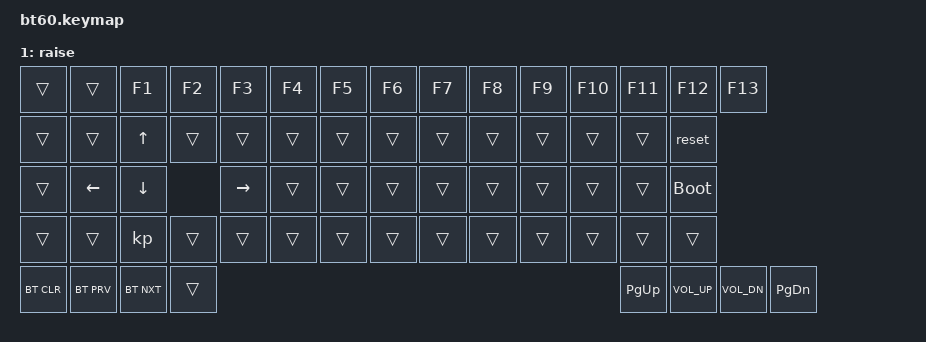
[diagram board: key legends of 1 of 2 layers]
#include <behaviors.dtsi>
#include <dt-bindings/zmk/keys.h>
#include <dt-bindings/zmk/bt.h>

/ {
	keymap {
		compatible = "zmk,keymap";

		default_layer {
				// ------------------------------------------------------------------------------------------
				// | ESC |  GRAVE |  1  |  2  |  3  |  4  |  5  |  6  |  7  |  8  |  9  |  0  |  -  |  =  |   "|"   |
				// | TAB  |  Q  |  W  |  E  |  R  |  T  |  Y  |  U  |  I  |  O  |  P  |  [  |  ]  |   BKSP   |
				// | CAPS  |  A  |  S  |  D  |  F  |  G  |  H  |  J  |  K  |  L  |  ;  |  '  |     ENTER    |
				// |  SHIFT    |  Z  |  X  |  C  |  V  |  B  |  N  |  M  |  ,  |  .  | /   |     SHIFT      |
				// |  CTL  |  ALT  |  CMD  |                     SPACE               |   LEFT   |  UP  | DOWN |  RIGHT |
				// ------------------------------------------------------------------------------------------
			bindings = <
				&kp ESC &kp GRAVE &kp N1 &kp N2 &kp N3 &kp N4 &kp N5 &kp N6 &kp N7 &kp  N8   &kp  N9 &kp  N0  &kp MINUS &kp EQUAL &kp BSLH
				&kp TAB  &kp Q  &kp W  &kp E  &kp R  &kp T  &kp Y  &kp U  &kp  I    &kp  O  &kp  P   &kp LBKT &kp RBKT  &kp BSPC
				&kp CLCK  &kp A  &kp S  &kp D  &kp F  &kp G  &kp H  &kp J  &kp  K    &kp  L  &kp SEMI &kp SQT           &kp RET
				&kp LSHFT  &kp Z  &kp X  &kp C  &kp V  &kp B  &kp N  &kp M  &kp COMMA &kp DOT &kp FSLH    &kp RSHFT    &mo 1
				&kp LCTRL &kp LALT &kp LCMD            &kp SPACE                          &kp LEFT &kp UP &kp DOWN &kp RIGHT
			>;
			sensor-bindings = <&inc_dec_kp C_VOL_UP C_VOL_DN>;
		};
		raise {
			bindings = <
				&trans &trans &kp F1 &kp F2 &kp F3 &kp F4 &kp F5 &kp F6 &kp F7 &kp  F8   &kp  F9 &kp  F10  &kp F11 &kp F12 &kp F13
				&trans &trans &kp UP &trans &trans &trans &trans &trans &trans &trans &trans &trans &trans &reset
				&trans &kp LEFT &kp DOWN &kp RIGHT &trans &trans &trans &trans &trans &trans &trans  &trans   &bootloader
				&trans &trans &kp &trans &trans &trans &trans &trans &trans &trans &trans &trans &trans  &trans
				&bt BT_CLR &bt BT_PRV  &bt BT_NXT                       &trans                 &kp PG_UP &kp C_VOL_UP &kp C_VOL_DN &kp PG_DN
			>;
			sensor-bindings = <&inc_dec_kp C_VOL_UP C_VOL_DN>;
		};
	};
};
